# STM32G411xC register map
File version: 1.0
Registers are 32-bit, read-write, reset 0x0 unless marked. A register's access mark holds for its fields unless they carry their own. Offsets are from the block's base; [hi:lo] are bit positions; {n}, {i} and the like mark numbered series; 'fields as' and 'values as' point back to an identical list.

## CORDIC
Base 0x40020C00
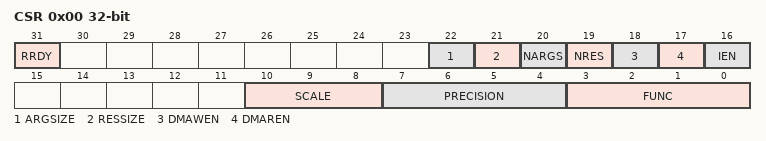
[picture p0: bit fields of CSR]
0x00 CSR — CORDIC control and status register
  [31] RRDY — Result Ready Flag
  [22] ARGSIZE — Width of input data
    0=INSIZE_32BITS (32 bits input data size (Q1.31 format)); 1=INSIZE_16BITS (16 bits input data size (Q1.15 format))
  [21] RESSIZE — Width of output data
    0=OUTSIZE_32BITS (32 bits output data size (Q1.31 format)); 1=OUTSIZE_16BITS (16 bits output data size (Q1.15 format))
  [20] NARGS — Number of arguments in RDATA register
    0=NBWRITE_1; 1=NBWRITE_2
  [19] NRES — Number of results in WDATA register
    0=NBREAD_1; 1=NBREAD_2
  [18] DMAWEN — DMA Write channel Enable
  [17] DMAREN — DMA Read channel Enable
  [16] IEN — Interrupt Enable
  [10:8] SCALE — Scaling factor
  [7:4] PRECISION
    1=PRECISION_1CYCLE; {v}=PRECISION_{v}CYCLES (v=2..15)
  [3:0] FUNC — Function
    0=COSINE; 1=SINE; 2=PHASE; 3=MODULUS; 4=ARCTANGENT; 5=HCOSINE (Hyperbolic Cosine); 6=HSINE (Hyperbolic Sine); 7=HARCTANGENT (Hyperbolic Arctangent); 8=NATURALLOG (Natural Logarithm); 9=SQUAREROOT
0x04 WDATA — CORDIC argument register
  [31:0] ARG — Input Argument
0x08 RDATA — CORDIC result register
  [31:0] RES — Output Result

## FMAC
Base 0x40021400
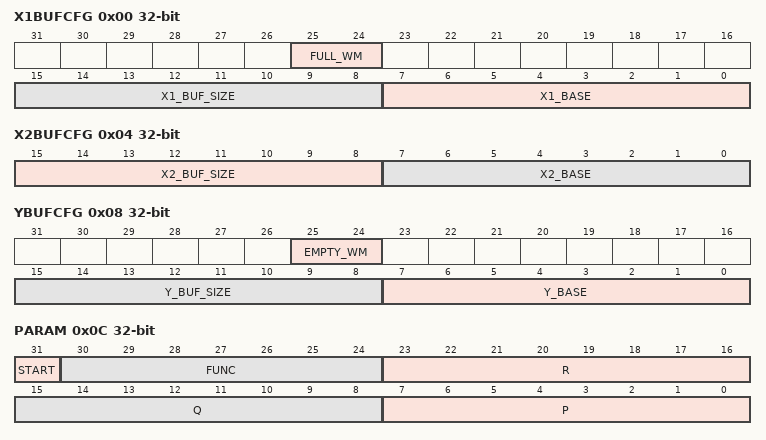
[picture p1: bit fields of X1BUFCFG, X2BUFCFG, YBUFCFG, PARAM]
0x00 X1BUFCFG — FMAC X1 Buffer Configuration register
  [25:24] FULL_WM — Watermark for buffer full flag
    0=WM_0_THRESHOLD_1; 1=WM_1_THRESHOLD_2; 2=WM_2_THRESHOLD_4; 3=WM_3_THRESHOLD_8
  [15:8] X1_BUF_SIZE — Allocated size of X1 buffer in 16-bit words
  [7:0] X1_BASE — Base address of X1 buffer
0x04 X2BUFCFG — FMAC X2 Buffer Configuration register
  [15:8] X2_BUF_SIZE — Size of X2 buffer in 16-bit words
  [7:0] X2_BASE — Base address of X2 buffer
0x08 YBUFCFG — FMAC Y Buffer Configuration register
  [25:24] EMPTY_WM — Watermark for buffer empty flag
    values as X1BUFCFG.FULL_WM
  [15:8] Y_BUF_SIZE — Size of Y buffer in 16-bit words
  [7:0] Y_BASE — Base address of Y buffer
0x0C PARAM — FMAC Parameter register
  [31] START — Enable execution
  [30:24] FUNC — Function
    1=LOAD_X1 (Load X1 buffer); 2=LOAD_X2 (Load X2 buffer); 3=LOAD_Y (Load Y buffer); 8=CONVO_FIR (Convolution (FIR filter)); 9=IIR_DIRECT_FORM_1 (IIR filter (direct form 1))
  [23:16] R — Input parameter R
  [15:8] Q — Input parameter Q
  [7:0] P — Input parameter P
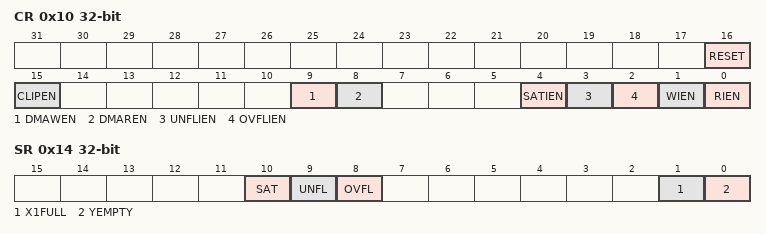
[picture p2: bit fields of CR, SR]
0x10 CR — FMAC Control register
  [16] RESET — Reset filter mathematical accelerator unit
  [15] CLIPEN — Enable clipping
  [9] DMAWEN — Enable DMA write channel requests
  [8] DMAREN — Enable DMA read channel requests
  [4] SATIEN — Enable saturation error interrupts
  [3] UNFLIEN — Enable underflow error interrupts
  [2] OVFLIEN — Enable overflow error interrupts
  [1] WIEN — Enable write interrupt
  [0] RIEN — Enable read interrupt
0x14 SR — FMAC Status register
  [10] SAT — Saturation error flag
  [9] UNFL — Underflow error flag
  [8] OVFL — Overflow error flag
  [1] X1FULL — X1 buffer full flag
  [0] YEMPTY — Y buffer empty flag
0x18 WDATA — FMAC Write Data register
  [15:0] WDATA — Write data
0x1C RDATA — FMAC Read Data register
  [15:0] RDATA — Read data

## FLASH — FLASH Registers
Base 0x40022000
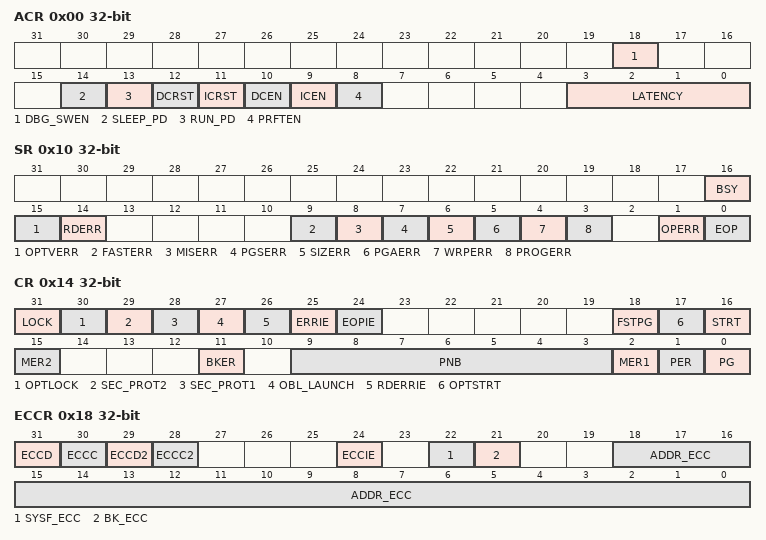
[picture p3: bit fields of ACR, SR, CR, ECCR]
0x00 ACR — FLASH access control register
  [18] DBG_SWEN — Software disable for debugger
  [14] SLEEP_PD — Flash power down mode during sleep
  [13] RUN_PD — Flash power down mode during run
  [12] DCRST
  [11] ICRST
  [10] DCEN
  [9] ICEN
  [8] PRFTEN
  [3:0] LATENCY
    0=FLASH Zero wait state; 1=FLASH One wait state; 2=FLASH Two wait states; 3=FLASH Three wait states; 4=FLASH Four wait states; 5=FLASH five wait state; 6=FLASH six wait state; 7=FLASH seven wait states; 8=FLASH eight wait states; 9=FLASH nine wait states; 10=FLASH ten wait states; 11=FLASH eleven wait states; 12=FLASH twelve wait states; 13=FLASH thirteen wait states; 14=FLASH fourteen wait states; 15=FLASH fifteen wait states
0x04 PDKEYR — FLASH power down key register
0x08 KEYR — FLASH key register
0x0C OPTKEYR — FLASH option key register
0x10 SR — FLASH status register
  [16] BSY, [15] OPTVERR, [14] RDERR, [9] FASTERR, [8] MISERR, [7] PGSERR, [6] SIZERR, [5] PGAERR, [4] WRPERR, [3] PROGERR, [1] OPERR, [0] EOP
0x14 CR — FLASH control register
  [31] LOCK, [30] OPTLOCK, [29] SEC_PROT2, [28] SEC_PROT1, [27] OBL_LAUNCH, [26] RDERRIE, [25] ERRIE, [24] EOPIE, [18] FSTPG, [17] OPTSTRT, [16] STRT, [15] MER2, [11] BKER, [9:3] PNB, [2] MER1, [1] PER, [0] PG
0x18 ECCR — FLASH ECC register
  [31] ECCD, [30] ECCC, [29] ECCD2, [28] ECCC2, [24] ECCIE, [22] SYSF_ECC, [21] BK_ECC, [18:0] ADDR_ECC
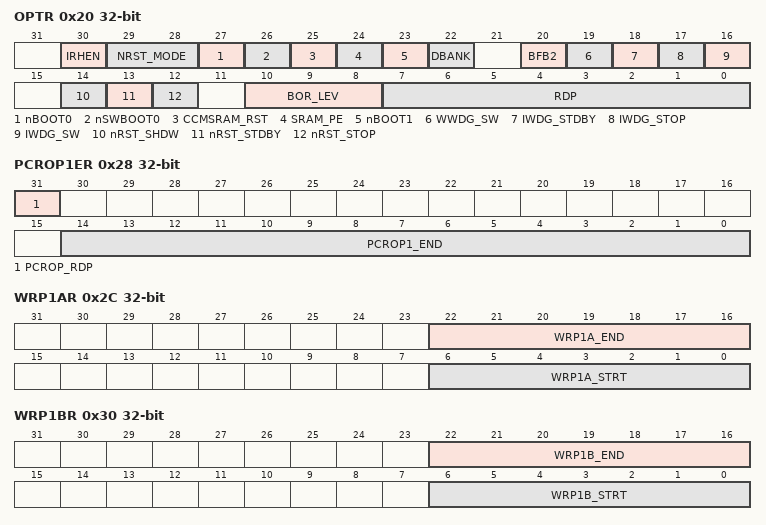
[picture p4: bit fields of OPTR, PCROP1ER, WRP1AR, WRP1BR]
0x20 OPTR — FLASH option register
  [30] IRHEN, [29:28] NRST_MODE, [27] nBOOT0, [26] nSWBOOT0, [25] CCMSRAM_RST, [24] SRAM_PE, [23] nBOOT1, [22] DBANK, [20] BFB2, [19] WWDG_SW, [18] IWDG_STDBY, [17] IWDG_STOP, [16] IWDG_SW, [14] nRST_SHDW, [13] nRST_STDBY, [12] nRST_STOP, [10:8] BOR_LEV, [7:0] RDP
0x24 PCROP1SR — FLASH bank1 PCROP start address register
  [14:0] PCROP1_STRT
0x28 PCROP1ER — FLASH bank1 PCROP end address register
  [31] PCROP_RDP, [14:0] PCROP1_END
0x2C WRP1AR — FLASH bank1 WRP area A address register
  [22:16] WRP1A_END, [6:0] WRP1A_STRT
0x30 WRP1BR — FLASH bank1 WRP area B address register
  [22:16] WRP1B_END, [6:0] WRP1B_STRT
0x44 PCROP2SR — FLASH bank2 PCROP start address register
  [14:0] PCROP2_STRT
0x48 PCROP2ER — FLASH bank2 PCROP end address register
  [14:0] PCROP2_END
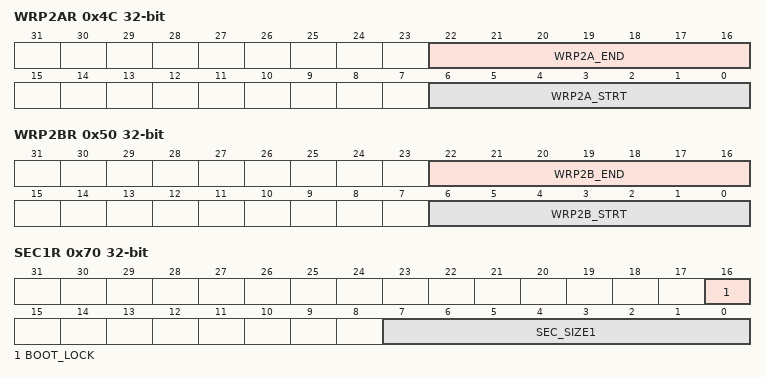
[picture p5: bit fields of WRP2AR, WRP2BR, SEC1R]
0x4C WRP2AR — FLASH bank2 WRP area A address register
  [22:16] WRP2A_END, [6:0] WRP2A_STRT
0x50 WRP2BR — FLASH bank2 WRP area B address register
  [22:16] WRP2B_END, [6:0] WRP2B_STRT
0x70 SEC1R — FLASH Securable memory register bank1
  [16] BOOT_LOCK, [7:0] SEC_SIZE1
0x74 SEC2R — FLASH Securable memory register bank2
  [7:0] SEC_SIZE2
